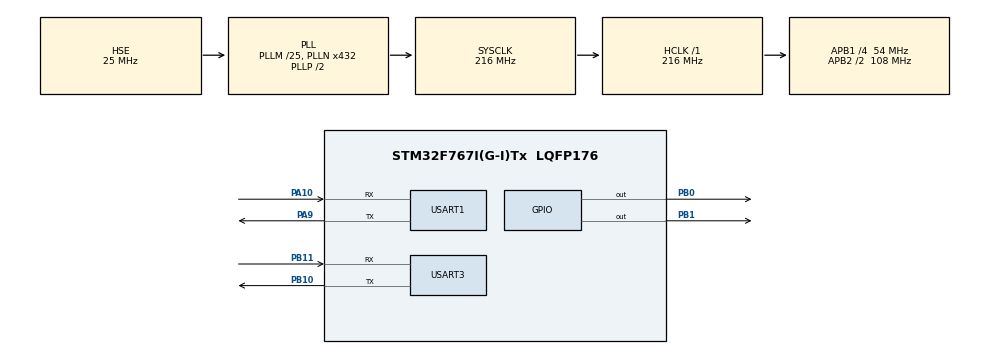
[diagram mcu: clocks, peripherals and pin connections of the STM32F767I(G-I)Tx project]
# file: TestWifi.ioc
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Dma.Request0=USART3_RX
Dma.USART3_RX.0.Direction=DMA_PERIPH_TO_MEMORY
Dma.USART3_RX.0.FIFOMode=DMA_FIFOMODE_DISABLE
Dma.USART3_RX.0.Instance=DMA1_Stream1
Dma.USART3_RX.0.MemDataAlignment=DMA_MDATAALIGN_BYTE
Dma.USART3_RX.0.MemInc=DMA_MINC_ENABLE
Dma.USART3_RX.0.Mode=DMA_CIRCULAR
Dma.USART3_RX.0.PeriphDataAlignment=DMA_PDATAALIGN_BYTE
Dma.USART3_RX.0.PeriphInc=DMA_PINC_DISABLE
Dma.USART3_RX.0.Priority=DMA_PRIORITY_MEDIUM
Mcu.Family=STM32F7
Mcu.Name=STM32F767I(G-I)Tx
Mcu.Package=LQFP176
NVIC.DMA1_Stream1_IRQn=true\:1\:0\:true\:false\:true\:false\:true
NVIC.PriorityGroup=NVIC_PRIORITYGROUP_4
NVIC.TIM3_IRQn=true\:0\:0\:false\:false\:true\:true\:true
NVIC.USART1_IRQn=true\:1\:0\:true\:false\:true\:true\:true
NVIC.USART3_IRQn=true\:2\:0\:true\:false\:true\:true\:true
PA10.Mode=Asynchronous
PA10.Signal=USART1_RX
PA9.Mode=Asynchronous
PA9.Signal=USART1_TX
PB0.Signal=GPIO_Output
PB1.Signal=GPIO_Output
PB10.Mode=Asynchronous
PB10.Signal=USART3_TX
PB11.Mode=Asynchronous
PB11.Signal=USART3_RX
PH0/OSC_IN.Mode=HSE-External-Oscillator
PH0/OSC_IN.Signal=RCC_OSC_IN
PH1/OSC_OUT.Mode=HSE-External-Oscillator
PH1/OSC_OUT.Signal=RCC_OSC_OUT
ProjectManager.HeapSize=0x200
ProjectManager.StackSize=0x400
ProjectManager.TargetToolchain=SW4STM32
RCC.AHBFreq_Value=216000000
RCC.APB1CLKDivider=RCC_HCLK_DIV4
RCC.APB1Freq_Value=54000000
RCC.APB1TimFreq_Value=108000000
RCC.APB2CLKDivider=RCC_HCLK_DIV2
RCC.APB2Freq_Value=108000000
RCC.APB2TimFreq_Value=216000000
RCC.CortexFreq_Value=216000000
RCC.HCLKFreq_Value=216000000
RCC.HSE_VALUE=25000000
RCC.HSI_VALUE=16000000
RCC.LSE_VALUE=32768
RCC.PLLM=25
RCC.PLLN=432
RCC.PLLSourceVirtual=RCC_PLLSOURCE_HSE
RCC.SYSCLKFreq_VALUE=216000000
RCC.SYSCLKSource=RCC_SYSCLKSOURCE_PLLCLK
RCC.USBFreq_Value=216000000
RCC.VCOOutputFreq_Value=432000000
TIM3.Period=999
TIM3.Prescaler=108
USART1.VirtualMode-Asynchronous=VM_ASYNC
USART3.VirtualMode-Asynchronous=VM_ASYNC
VP_TIM3_VS_ClockSourceINT.Mode=Internal
board=custom

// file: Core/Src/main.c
/* USER CODE BEGIN Header */
/**
  ******************************************************************************
  * @file           : main.c
  * @brief          : Main program body
  ******************************************************************************
  * @attention
  *
  * <h2><center>&copy; Copyright (c) 2021 STMicroelectronics.
  * All rights reserved.</center></h2>
  *
  * This software component is licensed by ST under BSD 3-Clause license,
  * the "License"; You may not use this file except in compliance with the
  * License. You may obtain a copy of the License at:
  *                        opensource.org/licenses/BSD-3-Clause
  *
  ******************************************************************************
  */
/* USER CODE END Header */
#include "main.h"
#include "dma.h"
#include "tim.h"
#include "usart.h"
#include "gpio.h"

/* USER CODE BEGIN Includes */
#include "string.h"
#include "Esp8266.h"
/* USER CODE END Includes */

void SystemClock_Config(void);

/* USER CODE BEGIN 0 */

extern u8 Wifi_Buff[Wifi_BuffSize];
extern u8 Wifi_data[Wifi_Size];
/* USER CODE END 0 */

int main(void)
{

  /* MCU Configuration--------------------------------------------------------*/

  /* Reset of all peripherals, Initializes the Flash interface and the Systick. */
  HAL_Init();

  /* Configure the system clock */
  SystemClock_Config();

  /* Initialize all configured peripherals */
  MX_GPIO_Init();
  MX_DMA_Init();
  MX_USART1_UART_Init();
  MX_USART3_UART_Init();
  MX_TIM3_Init();
  /* USER CODE BEGIN 2 */
   HAL_Delay(500);
   printf("Hello This is Stm32F767! ~ -.-\r\n");
   Wifi_Init();
   HAL_UART_Receive_IT(&huart1, (u8 *)Rx_Buff, 1);
  /* USER CODE END 2 */

  /* Infinite loop */
  while (1)
  {

    /* USER CODE BEGIN 3 */
    HAL_GPIO_TogglePin(GPIOB, GPIO_PIN_0);
    HAL_Delay(500);
  }
  /* USER CODE END 3 */
}

void SystemClock_Config(void)
{
  RCC_OscInitTypeDef RCC_OscInitStruct = {0};
  RCC_ClkInitTypeDef RCC_ClkInitStruct = {0};
  RCC_PeriphCLKInitTypeDef PeriphClkInitStruct = {0};

  /** Configure the main internal regulator output voltage
  */
  __HAL_RCC_PWR_CLK_ENABLE();
  __HAL_PWR_VOLTAGESCALING_CONFIG(PWR_REGULATOR_VOLTAGE_SCALE1);
  /** Initializes the RCC Oscillators according to the specified parameters
  * in the RCC_OscInitTypeDef structure.
  */
  RCC_OscInitStruct.OscillatorType = RCC_OSCILLATORTYPE_HSE;
  RCC_OscInitStruct.HSEState = RCC_HSE_ON;
  RCC_OscInitStruct.PLL.PLLState = RCC_PLL_ON;
  RCC_OscInitStruct.PLL.PLLSource = RCC_PLLSOURCE_HSE;
  RCC_OscInitStruct.PLL.PLLM = 25;
  RCC_OscInitStruct.PLL.PLLN = 432;
  RCC_OscInitStruct.PLL.PLLP = RCC_PLLP_DIV2;
  RCC_OscInitStruct.PLL.PLLQ = 2;
  if (HAL_RCC_OscConfig(&RCC_OscInitStruct) != HAL_OK)
  {
    Error_Handler();
  }
  /** Activate the Over-Drive mode
  */
  if (HAL_PWREx_EnableOverDrive() != HAL_OK)
  {
    Error_Handler();
  }
  /** Initializes the CPU, AHB and APB buses clocks
  */
  RCC_ClkInitStruct.ClockType = RCC_CLOCKTYPE_HCLK|RCC_CLOCKTYPE_SYSCLK
                              |RCC_CLOCKTYPE_PCLK1|RCC_CLOCKTYPE_PCLK2;
  RCC_ClkInitStruct.SYSCLKSource = RCC_SYSCLKSOURCE_PLLCLK;
  RCC_ClkInitStruct.AHBCLKDivider = RCC_SYSCLK_DIV1;
  RCC_ClkInitStruct.APB1CLKDivider = RCC_HCLK_DIV4;
  RCC_ClkInitStruct.APB2CLKDivider = RCC_HCLK_DIV2;

  if (HAL_RCC_ClockConfig(&RCC_ClkInitStruct, FLASH_LATENCY_7) != HAL_OK)
  {
    Error_Handler();
  }
  PeriphClkInitStruct.PeriphClockSelection = RCC_PERIPHCLK_USART1|RCC_PERIPHCLK_USART3;
  PeriphClkInitStruct.Usart1ClockSelection = RCC_USART1CLKSOURCE_PCLK2;
  PeriphClkInitStruct.Usart3ClockSelection = RCC_USART3CLKSOURCE_PCLK1;
  if (HAL_RCCEx_PeriphCLKConfig(&PeriphClkInitStruct) != HAL_OK)
  {
    Error_Handler();
  }
}

void Error_Handler(void)
{
  __disable_irq();
  while (1)
  {
  }
}

/************************ (C) COPYRIGHT STMicroelectronics *****END OF FILE****/
